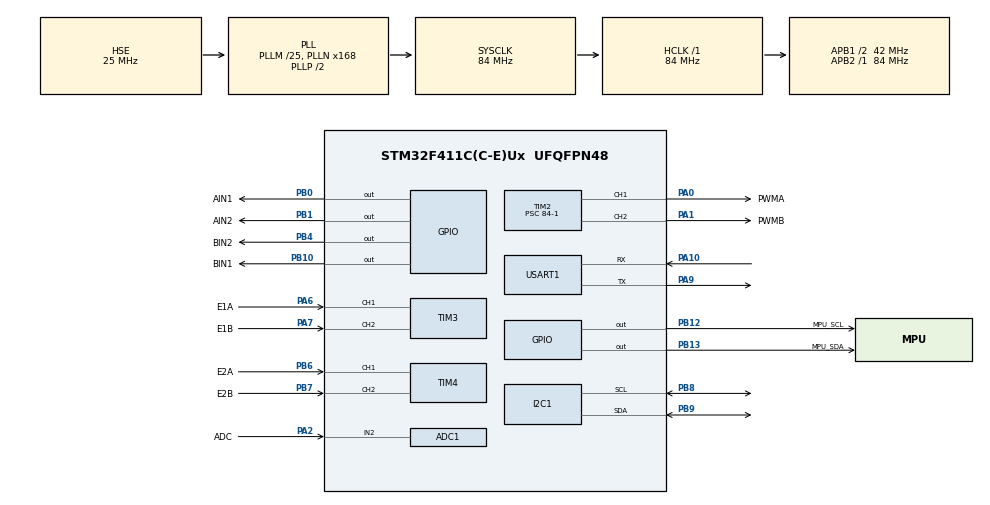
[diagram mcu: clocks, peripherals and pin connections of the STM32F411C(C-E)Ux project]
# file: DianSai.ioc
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ADC1.Channel-0\#ChannelRegularConversion=ADC_CHANNEL_2
ADC1.NbrOfConversionFlag=1
ADC1.Rank-0\#ChannelRegularConversion=1
ADC1.SamplingTime-0\#ChannelRegularConversion=ADC_SAMPLETIME_3CYCLES
ADC1.master=1
FREERTOS.Tasks01=defaultTask,24,128,StartDefaultTask,Default,NULL,Dynamic,NULL,NULL
Mcu.Family=STM32F4
Mcu.Name=STM32F411C(C-E)Ux
Mcu.Package=UFQFPN48
NVIC.PriorityGroup=NVIC_PRIORITYGROUP_4
NVIC.TIM1_UP_TIM10_IRQn=true\:15\:0\:false\:false\:true\:false\:false\:true\:true
NVIC.TIM2_IRQn=true\:5\:0\:false\:false\:true\:true\:true\:true\:true
NVIC.TimeBase=TIM1_UP_TIM10_IRQn
NVIC.TimeBaseIP=TIM1
PA0-WKUP.GPIO_Label=PWMA
PA0-WKUP.Signal=S_TIM2_CH1_ETR
PA1.GPIO_Label=PWMB
PA1.Signal=S_TIM2_CH2
PA10.Mode=Asynchronous
PA10.Signal=USART1_RX
PA13.Mode=Serial_Wire
PA13.Signal=SYS_JTMS-SWDIO
PA14.Mode=Serial_Wire
PA14.Signal=SYS_JTCK-SWCLK
PA2.GPIO_Label=ADC
PA2.Signal=ADCx_IN2
PA6.GPIO_Label=E1A
PA6.Signal=S_TIM3_CH1
PA7.GPIO_Label=E1B
PA7.Signal=S_TIM3_CH2
PA9.Mode=Asynchronous
PA9.Signal=USART1_TX
PB0.GPIO_Label=AIN1
PB0.Signal=GPIO_Output
PB1.GPIO_Label=AIN2
PB1.Signal=GPIO_Output
PB10.GPIO_Label=BIN1
PB10.Signal=GPIO_Output
PB12.GPIO_Label=MPU_SCL
PB12.GPIO_ModeDefaultOutputPP=GPIO_MODE_OUTPUT_OD
PB12.GPIO_PuPd=GPIO_NOPULL
PB12.Signal=GPIO_Output
PB13.GPIO_Label=MPU_SDA
PB13.GPIO_ModeDefaultOutputPP=GPIO_MODE_OUTPUT_OD
PB13.GPIO_PuPd=GPIO_NOPULL
PB13.Signal=GPIO_Output
PB4.GPIO_Label=BIN2
PB4.Signal=GPIO_Output
PB6.GPIO_Label=E2A
PB6.Signal=S_TIM4_CH1
PB7.GPIO_Label=E2B
PB7.Signal=S_TIM4_CH2
PB8.Mode=I2C
PB8.Signal=I2C1_SCL
PB9.Mode=I2C
PB9.Signal=I2C1_SDA
PC14-OSC32_IN.Mode=LSE-External-Oscillator
PC14-OSC32_IN.Signal=RCC_OSC32_IN
PC15-OSC32_OUT.Mode=LSE-External-Oscillator
PC15-OSC32_OUT.Signal=RCC_OSC32_OUT
PH0\ -\ OSC_IN.Mode=HSE-External-Oscillator
PH0\ -\ OSC_IN.Signal=RCC_OSC_IN
PH1\ -\ OSC_OUT.Mode=HSE-External-Oscillator
PH1\ -\ OSC_OUT.Signal=RCC_OSC_OUT
ProjectManager.HeapSize=0x200
ProjectManager.StackSize=0x1000
ProjectManager.TargetToolchain=MDK-ARM V5.32
RCC.48MHZClocksFreq_Value=42000000
RCC.AHBFreq_Value=84000000
RCC.APB1CLKDivider=RCC_HCLK_DIV2
RCC.APB1Freq_Value=42000000
RCC.APB1TimFreq_Value=84000000
RCC.APB2Freq_Value=84000000
RCC.APB2TimFreq_Value=84000000
RCC.CortexFreq_Value=84000000
RCC.HCLKFreq_Value=84000000
RCC.HSE_VALUE=25000000
RCC.HSI_VALUE=16000000
RCC.PLLM=25
RCC.PLLN=168
RCC.PLLSourceVirtual=RCC_PLLSOURCE_HSE
RCC.SYSCLKFreq_VALUE=84000000
RCC.SYSCLKSource=RCC_SYSCLKSOURCE_PLLCLK
RCC.VCOOutputFreq_Value=168000000
SH.ADCx_IN2.0=ADC1_IN2,IN2
SH.S_TIM2_CH1_ETR.0=TIM2_CH1,PWM Generation1 CH1
SH.S_TIM2_CH2.0=TIM2_CH2,PWM Generation2 CH2
SH.S_TIM3_CH1.0=TIM3_CH1,Encoder_Interface
SH.S_TIM3_CH2.0=TIM3_CH2,Encoder_Interface
SH.S_TIM4_CH1.0=TIM4_CH1,Encoder_Interface
SH.S_TIM4_CH2.0=TIM4_CH2,Encoder_Interface
TIM2.AutoReloadPreload=TIM_AUTORELOAD_PRELOAD_ENABLE
TIM2.Channel-PWM\ Generation1\ CH1=TIM_CHANNEL_1
TIM2.Channel-PWM\ Generation1\ No\ Output=TIM_CHANNEL_1
TIM2.Channel-PWM\ Generation2\ CH2=TIM_CHANNEL_2
TIM2.Channel-PWM\ Generation3\ CH3=TIM_CHANNEL_3
TIM2.Channel-PWM\ Generation4\ CH4=TIM_CHANNEL_4
TIM2.Period=1000-1
TIM2.Prescaler=84-1
TIM2.Pulse-PWM\ Generation1\ CH1=0
TIM2.Pulse-PWM\ Generation2\ CH2=0
USART1.VirtualMode=VM_ASYNC
VP_FREERTOS_VS_CMSIS_V2.Mode=CMSIS_V2
VP_SYS_VS_tim1.Mode=TIM1
VP_TIM2_VS_ClockSourceINT.Mode=Internal
board=custom

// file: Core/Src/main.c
/* USER CODE BEGIN Header */
/**
 ******************************************************************************
 * @file           : main.c
 * @brief          : Main program body
 ******************************************************************************
 * @attention
 *
 * Copyright (c) 2026 STMicroelectronics.
 * All rights reserved.
 *
 * This software is licensed under terms that can be found in the LICENSE file
 * in the root directory of this software component.
 * If no LICENSE file comes with this software, it is provided AS-IS.
 *
 ******************************************************************************
 */
/* USER CODE END Header */
#include "main.h"
#include "cmsis_os.h"
#include "adc.h"
#include "i2c.h"
#include "tim.h"
#include "usart.h"
#include "gpio.h"

/* USER CODE BEGIN Includes */
#include "app.h"
/* USER CODE END Includes */

void SystemClock_Config(void);
void MX_FREERTOS_Init(void);

int main(void)
{

  /* MCU Configuration--------------------------------------------------------*/

  /* Reset of all peripherals, Initializes the Flash interface and the Systick. */
  HAL_Init();

  /* Configure the system clock */
  SystemClock_Config();

  /* Initialize all configured peripherals */
  MX_GPIO_Init();
  MX_TIM2_Init();
  MX_I2C1_Init();
  MX_USART1_UART_Init();
  MX_ADC1_Init();
  MX_TIM3_Init();
  MX_TIM4_Init();
  /* USER CODE BEGIN 2 */
    App_Init();
  /* USER CODE END 2 */

  /* Init scheduler */
  osKernelInitialize();  /* Call init function for freertos objects (in cmsis_os2.c) */
  MX_FREERTOS_Init();

  /* Start scheduler */
  osKernelStart();

  /* We should never get here as control is now taken by the scheduler */

  /* Infinite loop */
    while (1)
    {

    }
}

void SystemClock_Config(void)
{
  RCC_OscInitTypeDef RCC_OscInitStruct = {0};
  RCC_ClkInitTypeDef RCC_ClkInitStruct = {0};

  /** Configure the main internal regulator output voltage
  */
  __HAL_RCC_PWR_CLK_ENABLE();
  __HAL_PWR_VOLTAGESCALING_CONFIG(PWR_REGULATOR_VOLTAGE_SCALE1);

  /** Initializes the RCC Oscillators according to the specified parameters
  * in the RCC_OscInitTypeDef structure.
  */
  RCC_OscInitStruct.OscillatorType = RCC_OSCILLATORTYPE_HSE;
  RCC_OscInitStruct.HSEState = RCC_HSE_ON;
  RCC_OscInitStruct.PLL.PLLState = RCC_PLL_ON;
  RCC_OscInitStruct.PLL.PLLSource = RCC_PLLSOURCE_HSE;
  RCC_OscInitStruct.PLL.PLLM = 25;
  RCC_OscInitStruct.PLL.PLLN = 168;
  RCC_OscInitStruct.PLL.PLLP = RCC_PLLP_DIV2;
  RCC_OscInitStruct.PLL.PLLQ = 4;
  if (HAL_RCC_OscConfig(&RCC_OscInitStruct) != HAL_OK)
  {
    Error_Handler();
  }

  /** Initializes the CPU, AHB and APB buses clocks
  */
  RCC_ClkInitStruct.ClockType = RCC_CLOCKTYPE_HCLK|RCC_CLOCKTYPE_SYSCLK
                              |RCC_CLOCKTYPE_PCLK1|RCC_CLOCKTYPE_PCLK2;
  RCC_ClkInitStruct.SYSCLKSource = RCC_SYSCLKSOURCE_PLLCLK;
  RCC_ClkInitStruct.AHBCLKDivider = RCC_SYSCLK_DIV1;
  RCC_ClkInitStruct.APB1CLKDivider = RCC_HCLK_DIV2;
  RCC_ClkInitStruct.APB2CLKDivider = RCC_HCLK_DIV1;

  if (HAL_RCC_ClockConfig(&RCC_ClkInitStruct, FLASH_LATENCY_2) != HAL_OK)
  {
    Error_Handler();
  }
}

void HAL_TIM_PeriodElapsedCallback(TIM_HandleTypeDef *htim)
{
  if (htim->Instance == TIM1)
  {
    HAL_IncTick();
  }
}

void Error_Handler(void)
{
    __disable_irq();
    while (1)
    {
    }
}

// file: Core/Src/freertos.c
/* USER CODE BEGIN Header */
/**
 ******************************************************************************
 * File Name          : freertos.c
 * Description        : Code for freertos applications
 ******************************************************************************
 * @attention
 *
 * Copyright (c) 2026 STMicroelectronics.
 * All rights reserved.
 *
 * This software is licensed under terms that can be found in the LICENSE file
 * in the root directory of this software component.
 * If no LICENSE file comes with this software, it is provided AS-IS.
 *
 ******************************************************************************
 */
/* USER CODE END Header */

#include "FreeRTOS.h"
#include "task.h"
#include "main.h"
#include "cmsis_os.h"

/* USER CODE BEGIN Includes */
#include "app.h"
/* USER CODE END Includes */

/* Definitions for defaultTask */

void StartDefaultTask(void *argument);

void MX_FREERTOS_Init(void); /* (MISRA C 2004 rule 8.1) */

void MX_FREERTOS_Init(void) {

  /* Create the thread(s) */
  /* creation of defaultTask */

  /* USER CODE BEGIN RTOS_THREADS */
    App_TaskCreate();
  /* USER CODE END RTOS_THREADS */

}

void StartDefaultTask(void *argument)
{
  for(;;)
  {
    osDelay(1);
  }
}
